# BlueNRG2 register map
Vendor: STMicroelectronics; Series: BlueNRG1; File version: 1.0.0
CPU: CM0 r0p0, little endian, no MPU, no FPU, 2 interrupt priority bits
Registers are 32-bit, read-write, reset 0x0 unless marked. A register's access mark holds for its fields unless they carry their own. Offsets are from the block's base; [hi:lo] are bit positions; {n}, {i} and the like mark numbered series; 'fields as' and 'values as' point back to an identical list.

## SPI — Serial peripheral interface
Base 0x40400000
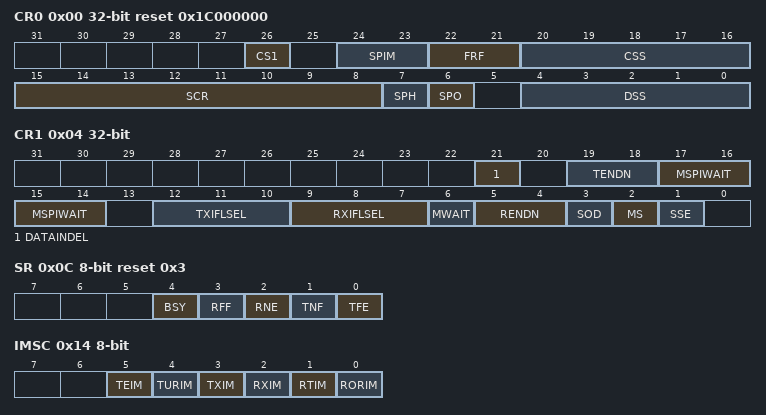
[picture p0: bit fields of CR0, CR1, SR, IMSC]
0x00 CR0 reset 0x1C000000 — Control Register 0
  [26] CS1 — Chip Selection for slave one<ul><li>0: the slave 1 is selected.</li><li>1: the slave 1 is not selected.</li></ul>
    0=CS1_NOT_SELECT (Slave 1 is select); 1=CS1_SELECT (Slave 1 is not select)
  [24:23] SPIM — SPI transmission mode.<ul><li>00b: Full duplex mode.</li><li>01b: Transmit mode.</li><li>10b: Receive mode.</li><li>11b: Combined mode.</li></ul>
    0=FULL_DUPLEX (SPI is configured in full duplex mode); 1=TRANSMIT (SPI is configured in transmit mode); 2=RECEIVE (SPI is configured in receive mode); 3=COMBINED (SPI is configured in combined mode)
  [22:21] FRF — Frame format.<ul><li>00b: Motorola SPI frame format.</li><li>10b: National MicroWire frame format.</li></ul>
    0=MOTOROLA (Motorola SPI frame format); 1=TI_SYNCHRONOUS_SERIAL (TI synchronous serial frame format); 2=NATIONAL_MICROWIRE (National MicroWire frame format); 3=UNIDIRECTIONAL (Unidirectional frame format)
  [20:16] CSS — Command Size Select (in MicroWire mode). (CSS+1) defines the number of bits:<ul><li>0x00: Reserved.</li><li>0x01: Reserved.</li><li>0x02: Reserved.</li><li>0x03: 4-bit data.</li><li>0x04: 5-bit data.</li><li>...</li><li>0x1F: 32-bit data.</li></ul>
    {v}=DATA_{v+1}BIT ({v+1}-bit data) (v=3..31)
  [15:8] SCR — Serial Clock Rate.<p>The SRC value is used to generate the transmit and receive bit rate of the SPI. The bit rate is: f_SPICLK / (CPSDVR * (1 + SCR)), where CPSDVR is an even value from 2 to 254 and SCR is a value from 0 to 255.</p>
  [7] SPH — Clock phase.<ul><li>0: Steady state of clock phase is low.</li><li>1: Steady state of clock phase is high.</li></ul>
    0=PHASE_0 (Received data is captured on the rising edge (SPO=0) or on the falling edge (SPO=1) of SSPCLKO. Transmitted data is sent on the falling edge (SPO=0) or on the rising edge (SPO=1) of SSPCLKO); 1=PHASE_1 (Received data is captured on the falling edge (SPO=0) or on the rising edge (SPO=1) of SSPCLKO.Transmitted data is sent on the rising edge (SPO=0) or on the falling edge (SPO=1) of SSPCLKO)
  [6] SPO — Clock polarity.<ul><li>0: Steady state of clock polarity is low.</li><li>1: Steady state of clock polarity is high.</li></ul>
    0=INACTIVE_LOW (The inactive or idle state of SSPCLKO is LOW); 1=INACTIVE_HIGH (The inactive or idle state of SSPCLKO is HIGH)
  [4:0] DSS — Data size select. (DSS+1) defines the number of bits:<ul><li>0x00: Reserved.</li><li>0x01: Reserved.</li><li>0x02: Reserved.</li><li>0x03: 4-bit data.</li><li>0x04: 5-bit data.</li><li>...</li><li>0x1F: 32-bit data.</li></ul>
    {v}=DATA_{v+1}BIT ({v+1}-bit data) (v=3..31)
0x04 CR1 — Control Register 1
  [21] DATAINDEL — Data input delay.<ul><li>0: No delay is inserted in data input.</li><li>1: A delay of 2 clock cycles is inserted in the data input path.</li></ul>
  [19:18] TENDN — Transmit endian format.<ul><li>00b: The element is transmitted MSByte-first and MSbit-first.</li><li>01b: The element is transmitted LSByte-first and MSbit-first.</li><li>10b: The element is transmitted MSByte-first and LSbit-first.</li><li>11b: The element is transmitted LSByte-first and LSbit-first.</li></ul>The cases 00b and 11b are set for data frame size from 4 to 32 bits. The cases 01b and 10b are set only for data frame size 16, 24 and 32 bits.
    0=MSB_FIRST_MSB_FIRST (The element is received MSByte-first and MSbit-first); 1=LSB_FIRST_MSB_FIRST (The element is received LSByte-first and MSbit-first); 2=MSB_FIRST_LSB_FIRST (The element is received MSByte-first and LSbit-first); 3=LSB_FIRST_LSB_FIRST (The element is received LSByte-first and LSbit-first)
  [17:14] MSPIWAIT — SPI Wait mode. This value is used to insert a wait state between frames.
  [12:10] TXIFLSEL — Transmit interrupt FIFO level select. This bit field selects the trigger points to transmit FIFO interrupt:<ul><li>000b: TX FIFO contains 1 element or more.</li><li>001b: TX FIFO contains 4 elements or more.</li><li>010b: TX FIFO contains 8 elements or more.</li><li>Others: Reserved.</li></ul>
    0=MIN_1ELEMENT (Tx FIFO contains 1 element or more); 1=MIN_4ELEMENTS (Tx FIFO contains 4 elements or more); 2=MIN_8ELEMENTS (Tx FIFO contains 8 elements or more)
  [9:7] RXIFLSEL — Receive interrupt FIFO level select. This bit field selects the trigger points to receive FIFO interrupt:<ul><li>000b: RX FIFO contains 1 element or more.</li><li>001b: RX FIFO contains 4 elements or more.</li><li>010b: RX FIFO contains 8 elements or more.</li><li>Others: Reserved.</li></ul>
    0=MIN_1ELEMENT (Rx FIFO contains 1 element or more); 1=MIN_4ELEMENTS (Rx FIFO contains 4 elements or more); 2=MIN_8ELEMENTS (Rx FIFO contains 8 elements or more)
  [6] MWAIT — MicroWire Wait Sate Bit Enable
    0=NO_WAIT (No wait state); 1=ONE_WAIT (One wait state)
  [5:4] RENDN — Receive endian format.<ul><li>00b: The element is received MSByte-first and MSbit-first.</li><li>01b: The element is received LSByte-first and MSbit-first.</li><li>10b: The element is received MSByte-first and LSbit-first.</li><li>11b: The element is received LSByte-first and LSbit-first.</li></ul>The cases 00b and 11b are set for data frame size from 4 to 32 bits. The cases 01b and 10b are set only for data frame size 16, 24 and 32 bits.
    values as TENDN
  [3] SOD — Slave mode output disable (slave mode only).<ul><li>0: SPI can drive the MISO signal in slave mode.</li><li>1: SPI must not drive the MISO signal in slave mode.</li></ul>In multiple slave system, it is possible for a SPI master to broadcast a message to all slaves in the system while ensuring only one slave drives data onto the serial output line MISO.
  [2] MS — Master or slave mode select.<ul><li>0: Master mode.</li><li>1: Slave mode.</li></ul>
    0=MASTER (Master mode); 1=SLAVE (Slave mode)
  [1] SSE — SPI enable.<ul><li>0: SPI disable.</li><li>1: SPI enable.</li></ul>
    0=DISABLE (SSP operation disable); 1=ENABLE (SSP operation enable)
0x08 DR — Data Register
  [31:0] DATA — Transmit/Receive data:<ul><li>Read: RX FIFO is read.</li><li>Write: TX FIFO is written.</li></ul>Data must be right-justified when a data size of less than 32-bit is programmed. Unused bits are ignored by the transmit logic. The receive logic automatically right-justifies data.
0x0C SR 8-bit ro reset 0x3 — Status Register
  [4] BSY — SPI busy flag:<ul><li>0: SPI is idle.</li><li>1: SPI is currently transmitting and/or receiving a frame or the TX FIFO is not empty.</li></ul>
  [3] RFF — Receive FIFO full:<ul><li>0: RX FIFO is not full.</li><li>1: RX FIFO is full.</li></ul>
  [2] RNE — Receive FIFO not empty:<ul><li>0: RX FIFO is empty.</li><li>1: RX FIFO is not empty.</li></ul>
  [1] TNF — Transmit FIFO not full:<ul><li>0: TX FIFO is full.</li><li>1: TX FIFO is not full.</li></ul>
  [0] TFE — Transmit FIFO empty:<ul><li>0: TX FIFO is not empty.</li><li>1: TX FIFO is empty.</li></ul>
0x10 CPSR 8-bit — Clock prescale register
  [7:0] CPSDVSR range 2..254 — Clock prescale divisor.It must be an even number from 2 to 254. The value is used to generate the transmit and receive bit rate of the SPI. The bit rate is:<p>FSSPCLK / [CPSDVR x (1+SCR)]</p>where SCR is a value from 0 to 255, programmed through the SSP_CR0 register.
0x14 IMSC 8-bit — Interrupt mask set or clear register
  [all] fields
    0=IRQ_DISABLE; 1=IRQ_ENABLE
  [5] TEIM — Transmit FIFO empty interrupt mask:<ul><li>0: TX FIFO empty interrupt is masked (irq disabled).</li><li>1: TX FIFO empty interrupt is not masked (irq enabled).</li></ul>
  [4] TURIM — Transmit underrun interrupt mask:<ul><li>0: Transmit underrun interrupt is masked (irq disabled).</li><li>1: Transmit underrun interrupt is not masked (irq enabled).</li></ul>
  [3] TXIM — Transmit FIFO interrupt mask:<ul><li>0: Transmit interrupt is masked (irq disabled).</li><li>1: Transmit interrupt is not masked (irq enabled).</li></ul>
  [2] RXIM — Receive FIFO interrupt mask:<ul><li>0: Receive interrupt is masked (irq disabled).</li><li>1: Receive interrupt is not masked (irq enabled).</li></ul>
  [1] RTIM — Receive timeout interrupt mask:<ul><li>0: RX FIFO not empty or no read prior to the timeout period interrupt is masked (irq disabled).</li><li>1: RX FIFO not empty or no read prior to the timeout period interrupt is not masked (irq enabled).</li></ul>
  [0] RORIM — Receive overrun interrupt mask:<ul><li>0: RX FIFO written to while full condition interrupt is masked (irq disabled).</li><li>1: RX FIFO written to while full condition interrupt is not masked (irq enabled).</li></ul>
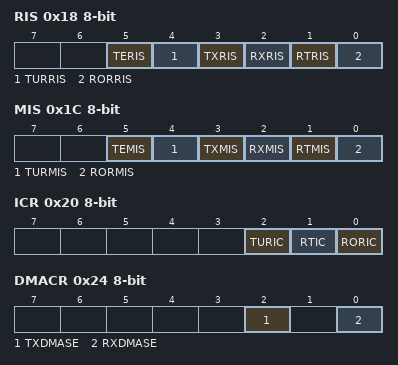
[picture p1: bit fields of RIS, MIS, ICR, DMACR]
0x18 RIS 8-bit ro — Raw interrupt status register
  [5] TERIS — Transmit FIFO Empty Raw Interrupt Status
  [4] TURRIS — Transmit underrun raw interrupt Status
  [3] TXRIS — Transmit raw interrupt status
  [2] RXRIS — Receive raw interrupt status
  [1] RTRIS — Receive time out raw interrupt status
  [0] RORRIS — Receive overrun raw interrupt status
0x1C MIS 8-bit ro — Masked Interrupt Status Register
  [5] TEMIS — Transmit FIFO Empty Masked Interrupt Status: gives the interrupt status after masking of the transmit FIFO empty interrupt.
  [4] TURMIS — Transmit Underrun Masked Interrupt Status: gives the interrupt status after masking of the transmit underrun interrupt.
  [3] TXMIS — Transmit Masked Interrupt Status: gives the interrupt status after masking of the transmit interrupt.
  [2] RXMIS — Receive Masked Interrupt Status: gives the interrupt status after masking of the receive interrupt.
  [1] RTMIS — Receive Time Out Masked Interrupt Status: gives the interrupt status after masking of receive timeout interrupt.
  [0] RORMIS — Receive Overrun Masked Interrupt Status: gives the interrupt status after masking of the receive overrun interrupt.
0x20 ICR 8-bit wo write-1-clears — Interrupt clear register
  [2] TURIC — Transmit Underrun Clear Interrupt: writing 1 clears the transmit overrun interrupt.
  [1] RTIC — Receive Time Out Clear Interrupt: writing 1 clears the receive timeout interrupt.
  [0] RORIC — Receive Overrun Clear Interrupt: writing 1 clears the receive overrun interrupt.
0x24 DMACR 8-bit — SPI DMA control register
  [2] TXDMASE — Signle transmit DMA request.<ul><li>0: Single transfer DMA in transmit disable.</li><li>1: Single transfer DMA in transmit enable.</li></ul>
    0=TX_DMA_DISABLE (Single transfer DMA in transmit disable); 1=TX_DMA_ENABLE (Single transfer DMA in transmit enable)
  [0] RXDMASE — Single receive DMA request.<ul><li>0: Single transfer DMA in receive disable.</li><li>1: Single transfer DMA in receive enable.</li></ul>
    0=RX_DMA_DISABLE (Single transfer DMA in receive disable); 1=RX_DMA_ENABLE (Single transfer DMA in receive enable)
0x28 RXFRM 16-bit — SPI Receive Frame register. Indicates the number of frames to receive from the slave.
0x2C CHN — Dummy character register
0x30 WDTXF 16-bit — SPI transmit FIFO receive frame number. Indicates the number of frames to receive from the transmit FIFO.
0x80 ITCR 8-bit — Integration test control register
  [1] SWAPFIFO — FIFO control mode:<ul><li>0: FIFO normal mode. Write in TDR register puts data in TX FIFO and read from TDR register read data from RX FIFO.</li><li>1: FIFO swapped mode. Write in TDR register puts data in RX FIFO and read from TDR register read data from TX FIFO.</li></ul>
    0=FIFO_NORMAL_MODE; 1=FIFO_TEST_MODE
0x8C TDR — FIFO Test Data Register
